# MSP430FR5969 register map
Vendor: msp430gen; File version: v0.4.0-24-gb954137
Registers are 16-bit, read-write, reset 0x0 unless marked. A register's access mark holds for its fields unless they carry their own. Offsets are from the block's base; [hi:lo] are bit positions; {n}, {i} and the like mark numbered series.

## CS — CS Clock System
Base 0x00000160
0x00 CSCTL0 — CS Control Register 0
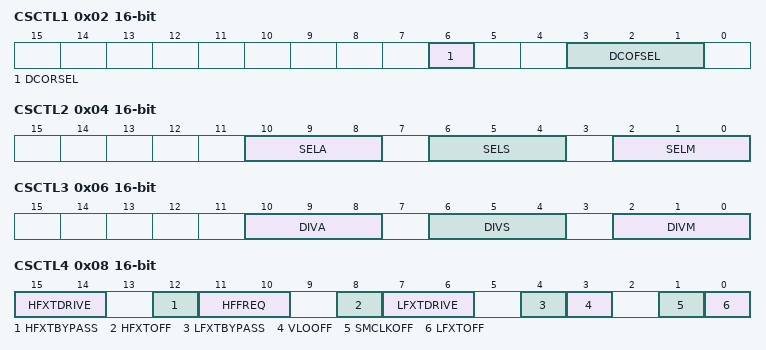
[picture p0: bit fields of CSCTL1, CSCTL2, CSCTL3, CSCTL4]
0x02 CSCTL1 — CS Control Register 1
  [6] DCORSEL — DCO range select.
  [3:1] DCOFSEL — DCO frequency select Bit: 0
    {v}=DCO frequency select: {v} (v=0..7)
0x04 CSCTL2 — CS Control Register 2
  [10:8] SELA — ACLK Source Select Bit: 0
    {v}=ACLK Source Select {v} (v=0..7)
  [6:4] SELS — SMCLK Source Select Bit: 0
    {v}=SMCLK Source Select {v} (v=0..7)
  [2:0] SELM — MCLK Source Select Bit: 0
    {v}=MCLK Source Select {v} (v=0..7)
0x06 CSCTL3 — CS Control Register 3
  [10:8] DIVA — ACLK Divider Bit: 0
    {v}=ACLK Source Divider {v} (v=0..5)
  [6:4] DIVS — SMCLK Divider Bit: 0
    {v}=SMCLK Source Divider {v} (v=0..5)
  [2:0] DIVM — MCLK Divider Bit: 0
    {v}=MCLK Source Divider {v} (v=0..5)
0x08 CSCTL4 — CS Control Register 4
  [15:14] HFXTDRIVE — HFXT Drive Level mode Bit 0
    {v}=HFXT Drive Level mode: {v} (v=0..3)
  [12] HFXTBYPASS — HFXT bypass mode : 0: internal 1:sourced from external pin
  [11:10] HFFREQ — HFXT frequency selection Bit 1
    {v}=HFXT frequency selection: {v} (v=0..3)
  [8] HFXTOFF — High Frequency Oscillator disable
  [7:6] LFXTDRIVE — LFXT Drive Level mode Bit 0
    {v}=LFXT Drive Level mode: {v} (v=0..3)
  [4] LFXTBYPASS — LFXT bypass mode : 0: internal 1:sourced from external pin
  [3] VLOOFF
  [1] SMCLKOFF
  [0] LFXTOFF — Low Frequency Oscillator (LFXT) disable
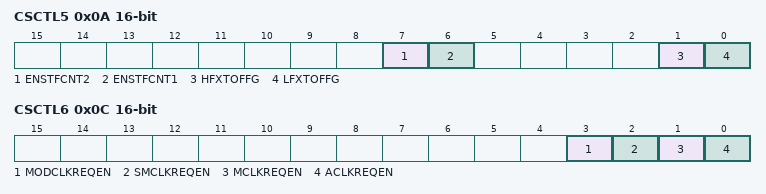
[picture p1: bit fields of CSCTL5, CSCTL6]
0x0A CSCTL5 — CS Control Register 5
  [7] ENSTFCNT2 — Enable start counter for XT2
  [6] ENSTFCNT1 — Enable start counter for XT1
  [1] HFXTOFFG — HFXT High Frequency Oscillator Fault Flag
  [0] LFXTOFFG — LFXT Low Frequency Oscillator Fault Flag
0x0C CSCTL6 — CS Control Register 6
  [3] MODCLKREQEN — MODOSC Clock Request Enable
  [2] SMCLKREQEN — SMCLK Clock Request Enable
  [1] MCLKREQEN — MCLK Clock Request Enable
  [0] ACLKREQEN — ACLK Clock Request Enable

## SYS — SYS System Module
Base 0x00000180
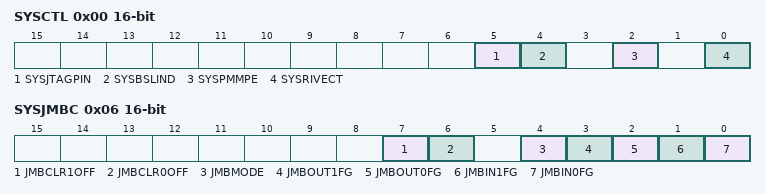
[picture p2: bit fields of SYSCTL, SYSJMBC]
0x00 SYSCTL — System control
  [5] SYSJTAGPIN — SYS - Dedicated JTAG pins enabled
  [4] SYSBSLIND — SYS - TCK/RST indication detected
  [2] SYSPMMPE — SYS - PMM access protect
  [0] SYSRIVECT — SYS - RAM based interrupt vectors
0x06 SYSJMBC — JTAG mailbox control
  [7] JMBCLR1OFF — SYS - Incoming JTAG Mailbox 1 Flag auto-clear disalbe
  [6] JMBCLR0OFF — SYS - Incoming JTAG Mailbox 0 Flag auto-clear disalbe
  [4] JMBMODE — SYS - JMB 16/32 Bit Mode
  [3] JMBOUT1FG — SYS - Outgoing JTAG Mailbox 1 Flag
  [2] JMBOUT0FG — SYS - Outgoing JTAG Mailbox 0 Flag
  [1] JMBIN1FG — SYS - Incoming JTAG Mailbox 1 Flag
  [0] JMBIN0FG — SYS - Incoming JTAG Mailbox 0 Flag
0x08 SYSJMBI0 — JTAG mailbox input 0
0x0A SYSJMBI1 — JTAG mailbox input 1
0x0C SYSJMBO0 — JTAG mailbox output 0
0x0E SYSJMBO1 — JTAG mailbox output 1
0x1A SYSUNIV — User NMI vector generator
0x1C SYSSNIV — System NMI vector generator
0x1E SYSRSTIV — Reset vector generator

## SHARED_REFERENCE
Base 0x000001B0
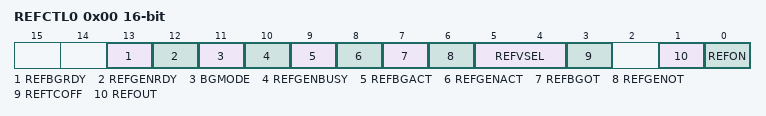
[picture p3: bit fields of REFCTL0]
0x00 REFCTL0 — REF Shared Reference control register 0
  [13] REFBGRDY — REF Reference bandgap ready
  [12] REFGENRDY — REF Reference generator ready
  [11] BGMODE — REF Bandgap mode
  [10] REFGENBUSY — REF Reference generator busy
  [9] REFBGACT — REF Reference bandgap active
  [8] REFGENACT — REF Reference generator active
  [7] REFBGOT — REF Bandgap and bandgap buffer one-time trigger
  [6] REFGENOT — REF Reference generator one-time trigger
  [5:4] REFVSEL — REF Reference Voltage Level Select Bit:0
    0=REF Reference Voltage Level Select 1.2V; 1=REF Reference Voltage Level Select 2.0V; 2=REF Reference Voltage Level Select 2.5V; 3=REF Reference Voltage Level Select 2.5V
  [3] REFTCOFF — REF Temp.Sensor off
  [1] REFOUT — REF Reference output Buffer On
  [0] REFON — REF Reference On
